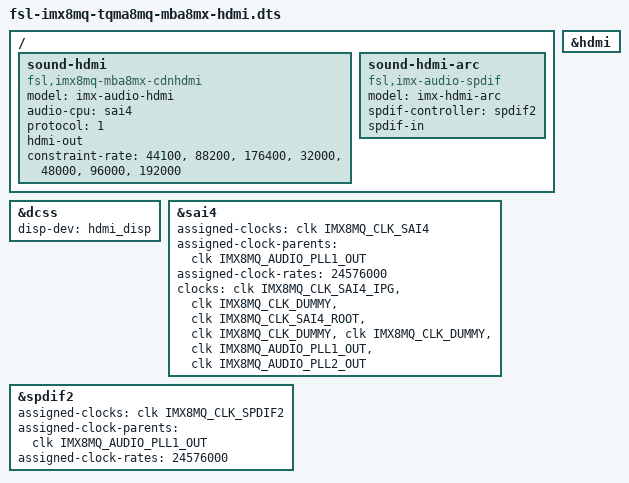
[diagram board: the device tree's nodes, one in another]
/*
 * Copyright 2019 TQ Systems GmbH
 *
 * This program is free software; you can redistribute it and/or
 * modify it under the terms of the GNU General Public License
 * as published by the Free Software Foundation; either version 2
 * of the License, or (at your option) any later version.
 *
 * This program is distributed in the hope that it will be useful,
 * but WITHOUT ANY WARRANTY; without even the implied warranty of
 * MERCHANTABILITY or FITNESS FOR A PARTICULAR PURPOSE.  See the
 * GNU General Public License for more details.
 */

#include "fsl-imx8mq-tqma8mq-mba8mx.dts"

/ {
	sound-hdmi {
		compatible = "fsl,imx8mq-mba8mx-cdnhdmi",
				"fsl,imx8mq-evk-cdnhdmi",
				"fsl,imx-audio-cdnhdmi";
		model = "imx-audio-hdmi";
		audio-cpu = <&sai4>;
		protocol = <1>;
		hdmi-out;
		constraint-rate = <44100>,
				<88200>,
				<176400>,
				<32000>,
				<48000>,
				<96000>,
				<192000>;
		status = "okay";
	};

	sound-hdmi-arc {
		compatible = "fsl,imx-audio-spdif";
		model = "imx-hdmi-arc";
		spdif-controller = <&spdif2>;
		spdif-in;
		status = "okay";
	};
};

&dcss {
	status = "okay";

	disp-dev = "hdmi_disp";
};

&hdmi {
	status = "okay";
};

&sai4 {
	assigned-clocks = <&clk IMX8MQ_CLK_SAI4>;
	assigned-clock-parents = <&clk IMX8MQ_AUDIO_PLL1_OUT>;
	assigned-clock-rates = <24576000>;
	clocks = <&clk IMX8MQ_CLK_SAI4_IPG>, <&clk IMX8MQ_CLK_DUMMY>,
		<&clk IMX8MQ_CLK_SAI4_ROOT>, <&clk IMX8MQ_CLK_DUMMY>,
		<&clk IMX8MQ_CLK_DUMMY>, <&clk IMX8MQ_AUDIO_PLL1_OUT>,
		<&clk IMX8MQ_AUDIO_PLL2_OUT>;
	clock-names = "bus", "mclk0", "mclk1", "mclk2", "mclk3", "pll8k", "pll11k";
	status = "okay";
};

&spdif2 {
	assigned-clocks = <&clk IMX8MQ_CLK_SPDIF2>;
	assigned-clock-parents = <&clk IMX8MQ_AUDIO_PLL1_OUT>;
	assigned-clock-rates = <24576000>;
	status = "okay";
};
